# USB0_VBP2APB_WRAP_CONTROLLER_VBP_CORE_ADDR_MAP register map
Vendor: Texas Instruments
Registers are 32-bit, access per field, reset 0x0 unless marked. A register's access mark holds for its fields unless they carry their own. Offsets are as the file gives them; [hi:lo] are bit positions; {n}, {i} and the like mark numbered series.

## USB0_VBP2APB_WRAP_CONTROLLER_VBP_CORE_ADDR_MAP (part 9 of 9)
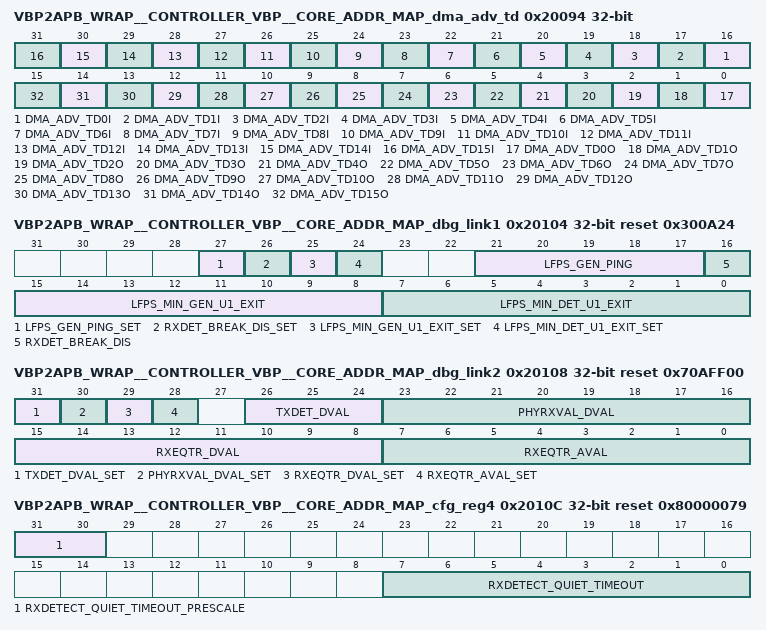
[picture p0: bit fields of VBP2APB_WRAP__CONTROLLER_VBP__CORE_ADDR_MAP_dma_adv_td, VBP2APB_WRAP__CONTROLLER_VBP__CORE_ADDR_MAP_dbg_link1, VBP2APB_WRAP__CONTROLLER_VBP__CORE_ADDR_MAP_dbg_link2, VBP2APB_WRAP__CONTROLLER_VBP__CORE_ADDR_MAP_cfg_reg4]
0x20094 VBP2APB_WRAP__CONTROLLER_VBP__CORE_ADDR_MAP_dma_adv_td rw — DMA Advance TD configuration Register (0 - when stopped during transfer, DMA will advance its address only to the next TRB (+12) start address. 1 - when stopped during transfer (e.g. on USB short packet received in TDL_FROM_TRB mode) DMA will advance its address to the next TD start address). Bits 0..15 applies to EPOUT0..EPOUT15 and bits 16..31 applies to EPIN0..EPIN15
  [n+16] DMA_ADV_TD{n}I (n=0..15) — DMA Advance TD configuration Register for selected Endpoint.
  [n] DMA_ADV_TD{n}O (n=0..15) — DMA Advance TD configuration Register for selected Endpoint.
0x20100 VBP2APB_WRAP__CONTROLLER_VBP__CORE_ADDR_MAP_cfg_reg1 reset 0x38000 — VBUS debouncer Configuration Register 1
  [17:0] DEBOUNCER_CNT rw — This parameter defines the VBUS debouncer delay i.e. the time interval between the VBUS detection on device input and the start of using it internally. Resolution of this parameter is 128 ns. For simulation purposes it is recommended to set the value 1 [128ns] For synthesis purposes it is recommended to set the value 230000 [~30ms]
0x20104 VBP2APB_WRAP__CONTROLLER_VBP__CORE_ADDR_MAP_dbg_link1 reset 0x300A24 — USB3.0 Configuration Register 2
  [27] LFPS_GEN_PING_SET wo — Set the LFPS_GEN_PING_SET value Writing '1' to this bit writes the LFPS_GEN_PING field value to the device. This bit is automatically cleared. Writing '0' has no effect.
  [26] RXDET_BREAK_DIS_SET wo — Set the RXDET_BREAK_DIS value Writing '1' to this bit writes the RXDET_BREAK_DIS field value to the device. This bit is automatically cleared. Writing '0' has no effect.
  [25] LFPS_MIN_GEN_U1_EXIT_SET wo — Set the LFPS_MIN_GEN_U1_EXIT value Writing '1' to this bit writes the LFPS_MIN_GEN_U1_EXIT field value to the device. This bit is automatically cleared. Writing '0' has no effect.
  [24] LFPS_MIN_DET_U1_EXIT_SET wo — Set the LFPS_MIN_DET_U1_EXIT value Writing '1' to this bit writes the LFPS_MIN_DET_U1_EXIT field value to the device. This bit is automatically cleared. Writing '0' has no effect.
  [21:17] LFPS_GEN_PING rw — LFPS_GEN_PING value This parameter configures the LFPS.Ping generation time as shown in the chapter 4. This field is saved to the device only when the field LFPS_GEN_PING_SET is set to '1' during write to the DBG_LINK1 register. Resolution of this parameter is 8 ns. For simulation purposes it is recommended to set the value 24 [~200ns] For synthesis purposes it is recommended to set the value 24 [~200ns]
  [16] RXDET_BREAK_DIS rw — RXDET_BREAK_DIS value This parameter configures terminating the Far-end Receiver termination detection sequence: '0': it is possible that USBSS_DEV will terminate Far-end receiver termination detection sequence '1': USBSS_DEV will not terminate Far-end receiver termination detection sequence The impact of the bit to the link behaviour is shown in chapter 4. This field is saved to the device only when the field RXDET_BREAK_DIS_SET is set to '1' during write to the DBG_LINK1 register.
  [15:8] LFPS_MIN_GEN_U1_EXIT rw — LFPS_MIN_GEN_U1_EXIT value This parameter configures the minimum time for phytxelecidle deassertion when LFPS.U1_Exit signalling is generated as shown in the chapter 4. This field is saved to the device only when the field LFPS_MIN_GEN_U1_EXIT_SET is set to '1' during write to the DBG_LINK1 register. Resolution of this parameter is 8 ns. For simulation purposes it is recommended to set the value 87 [~696ns] For synthesis purposes it is recommended to set the value 87 [~696ns]
  [7:0] LFPS_MIN_DET_U1_EXIT rw — LFPS_MIN_DET_U1_EXIT value This parameter configures the minimum time required for decoding the received LFPS as an LFPS.U1_Exit. Example is shown in the chapter 4. This field is saved to the device only when the field LFPS_MIN_DET_U1_EXIT_SET is set to '1' during write to the DBG_LINK1 register. Resolution of this parameter is 8 ns. For simulation purposes it is recommended to set the value 36 [~300ns]. For synthesis purposes it is recommended to set the value 36 [~300ns].
0x20108 VBP2APB_WRAP__CONTROLLER_VBP__CORE_ADDR_MAP_dbg_link2 reset 0x70AFF00 — USB3.0 Configuration Register 3
  [31] TXDET_DVAL_SET wo — Set the TXDET deassertion value Writing '1' to this bit writes the TXDET_DVAL field value to the device. This bit is automatically cleared. Writing '0' has no effect.
  [30] PHYRXVAL_DVAL_SET wo — Set the Phyrxvalid latency deassertion value Writing '1' to this bit writes the PHYRXVAL_DVAL field value to the device. This bit is automatically cleared. Writing '0' has no effect.0
  [29] RXEQTR_DVAL_SET wo — Set the rxeqtraining deassertion value Writing '1' to this bit writes the RXEQTR_DVAL field value to the device. This bit is automatically cleared. Writing '0' has no effect.
  [28] RXEQTR_AVAL_SET wo — Set the rxeqtraining assertion value Writing '1' to this bit writes the RXEQTR_AVAL field value to the device. This bit is automatically cleared. Writing '0' has no effect.
  [26:24] TXDET_DVAL rw — TXDET deassertion value This parameter configures the phytxdetrx_loop deassertion time after phystatus deassertion during Far-end receiver termination sequence as shown in the chapter 4. This field is saved to the device only when the field TXDET_DVAL_SET is set to '1' during write to the DBG_LINK2 register.
  [23:16] PHYRXVAL_DVAL rw — Phyrxvalid latency deassertion value This parameter enables extending internal phyrxdata and phyrxdatak validity as shown in the chapter 4. This field is saved to the device only when the field PHYRXVAL_DVAL_SET is set to '1' during write to the DBG_LINK2 register.
  [15:8] RXEQTR_DVAL rw — Rxeqtraining deassertion value This parameter configures phyrxeqtraining deasserting time as shown in the chapter 4. This field is saved to the device only when the field RXEQTR_DVAL_SET is set to '1' during write to the DBG_LINK2 register.
  [7:0] RXEQTR_AVAL rw — Rxeqtraining assertion value This parameter configures phyrxeqtraining asserting time as shown in the chapter 4. This field is saved to the device only when the field RXEQTR_AVAL_SET is set to '1' during write to the DBG_LINK2 register.
0x2010C VBP2APB_WRAP__CONTROLLER_VBP__CORE_ADDR_MAP_cfg_reg4 reset 0x80000079 — USB3.0 Configuration Register 4
  [31:30] RXDETECT_QUIET_TIMEOUT_PRESCALE rw — PRESCALER for RXDETECT_QUIET_TIMEOUT : - 0x0 : 8ns [PHY pclk clock] - 0x1 : 1us - 0x2 : 100us - 0x3 : no clock - allows disabling certain timeout
  [7:0] RXDETECT_QUIET_TIMEOUT rw — RXDETECT_QUIET_TIMEOUT value Resolution of this parameter is selected by RXDETECT_QUIET_TIMEOUT_PRESCALE. For simulation purposes it is recommended to set the value: - 11*100us =~1ms [SystemC device ENV] - 13*1us =~12us [VIP based ENV] For synthesis purposes it is recommended to set the value 121*100us =~12ms
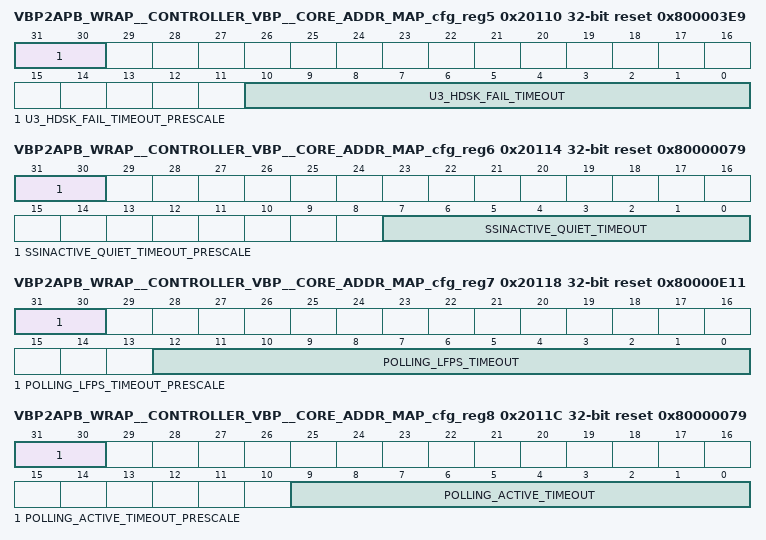
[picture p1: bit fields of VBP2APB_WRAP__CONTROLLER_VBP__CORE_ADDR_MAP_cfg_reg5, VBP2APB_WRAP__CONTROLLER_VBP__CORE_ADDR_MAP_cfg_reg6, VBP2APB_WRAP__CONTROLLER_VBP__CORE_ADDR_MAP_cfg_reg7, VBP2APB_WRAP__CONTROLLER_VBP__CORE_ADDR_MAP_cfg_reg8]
0x20110 VBP2APB_WRAP__CONTROLLER_VBP__CORE_ADDR_MAP_cfg_reg5 reset 0x800003E9 — USB3.0 Configuration Register 5
  [31:30] U3_HDSK_FAIL_TIMEOUT_PRESCALE rw — PRESCALER for U3_HDSK_FAIL_TIMEOUT : - 0x0 : 8ns [PHY pclk clock] - 0x1 : 1us - 0x2 : 100us - 0x3 : no clock - allows disabling certain timeout
  [10:0] U3_HDSK_FAIL_TIMEOUT rw — U3_HDSK_FAIL_TIMEOUT value Resolution of this parameter is selected by U3_HDSK_FAIL_TIMEOUT_PRESCALE. For simulation purposes it is recommended to set the value: - 11*100us =~1ms [SystemC device ENV] - 11*100us =~1ms [VIP based ENV] For synthesis purposes it is recommended to set the value 1001*100us =~100ms
0x20114 VBP2APB_WRAP__CONTROLLER_VBP__CORE_ADDR_MAP_cfg_reg6 reset 0x80000079 — Configuration Register 6
  [31:30] SSINACTIVE_QUIET_TIMEOUT_PRESCALE rw — PRESCALER for SSINACTIVE_QUIET_TIMEOUT value: - 0x0 : 8ns [PHY pclk clock] - 0x1 : 1us - 0x2 : 100us - 0x3 : no clock - allows disabling certain timeout
  [7:0] SSINACTIVE_QUIET_TIMEOUT rw — SSINACTIVE_QUIET_TIMEOUT value Resolution of this parameter is selected by SSINACTIVE_QUIET_TIMEOUT_PRESCALE. For simulation purposes it is recommended to set the value: - 11*100us =~1ms [SystemC device ENV] - 13*1us =~12us [VIP based ENV] For synthesis purposes it is recommended to set the value: - 121*100us =~12ms
0x20118 VBP2APB_WRAP__CONTROLLER_VBP__CORE_ADDR_MAP_cfg_reg7 reset 0x80000E11 — USB3.0 Configuration Register 7
  [31:30] POLLING_LFPS_TIMEOUT_PRESCALE rw — PRESCALER for POLLING_LFPS_TIMEOUT value: - 0x0 : 8ns [PHY pclk clock] - 0x1 : 1us - 0x2 : 100us - 0x3 : no clock - allows disabling certain timeout
  [12:0] POLLING_LFPS_TIMEOUT rw — POLLING_LFPS_TIMEOUT value Resolution of this parameter is selected by POLLING_LFPS_TIMEOUT_PRESCALE. For simulation purposes it is recommended to set the value: - 11*100us =~1ms [SystemC device ENV] - 481*1us =~480us [VIP based ENV] For synthesis purposes it is recommended to set the value: - 3601*100us =~360ms
0x2011C VBP2APB_WRAP__CONTROLLER_VBP__CORE_ADDR_MAP_cfg_reg8 reset 0x80000079 — USB3.0 Configuration Register 8
  [31:30] POLLING_ACTIVE_TIMEOUT_PRESCALE rw — PRESCALER for POLLING_ACTIVE_TIMEOUT value: - 0x0 : 8ns [PHY pclk clock] - 0x1 : 1us - 0x2 : 100us - 0x3 : no clock - allows disabling certain timeout
  [9:0] POLLING_ACTIVE_TIMEOUT rw — POLLING_ACTIVE_TIMEOUT value Resolution of this parameter is selected by POLLING_ACTIVE_TIMEOUT_PRESCALE. For simulation purposes it is recommended to set the value: - 11*100us =~1ms [SystemC device ENV] - 31*1us =~30us [VIP based ENV] For synthesis purposes it is recommended to set the value: - 121*100us =~12ms
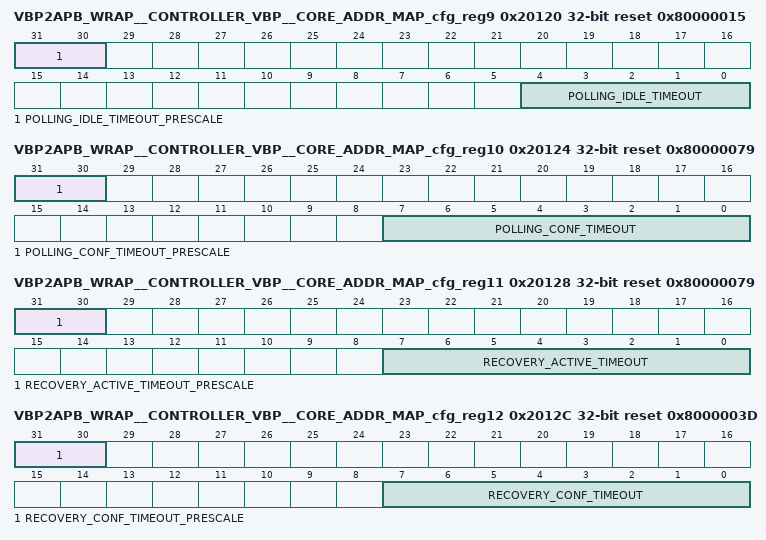
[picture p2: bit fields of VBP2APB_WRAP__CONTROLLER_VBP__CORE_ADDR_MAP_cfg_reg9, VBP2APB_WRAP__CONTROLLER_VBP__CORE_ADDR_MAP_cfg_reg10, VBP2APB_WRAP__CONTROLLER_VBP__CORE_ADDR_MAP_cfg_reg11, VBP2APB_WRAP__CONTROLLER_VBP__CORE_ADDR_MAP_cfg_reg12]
0x20120 VBP2APB_WRAP__CONTROLLER_VBP__CORE_ADDR_MAP_cfg_reg9 reset 0x80000015 — USB3.0 Configuration Register 9
  [31:30] POLLING_IDLE_TIMEOUT_PRESCALE rw — PRESCALER for POLLING_IDLE_TIMEOUT value: - 0x0 : 8ns [PHY pclk clock] - 0x1 : 1us - 0x2 : 100us - 0x3 : no clock - allows disabling certain timeout
  [4:0] POLLING_IDLE_TIMEOUT rw — POLLING_IDLE_TIMEOUT value Resolution of this parameter is selected by POLLING_IDLE_TIMEOUT_PRESCALE. For simulation purposes it is recommended to set the value: - 21*100us =~2ms [SystemC device ENV] - 3*1us =~2us [VIP based ENV] For synthesis purposes it is recommended to set the value: - 21*100us =~2ms
0x20124 VBP2APB_WRAP__CONTROLLER_VBP__CORE_ADDR_MAP_cfg_reg10 reset 0x80000079 — USB3.0 Configuration Register 10
  [31:30] POLLING_CONF_TIMEOUT_PRESCALE rw — PRESCALER for POLLING_CONF_TIMEOUT value: - 0x0 : 8ns [PHY pclk clock] - 0x1 : 1us - 0x2 : 100us - 0x3 : no clock - allows disabling certain timeout
  [7:0] POLLING_CONF_TIMEOUT rw — POLLING_CONF_TIMEOUT value Resolution of this parameter is selected by POLLING_CONF_TIMEOUT_PRESCALE. For simulation purposes it is recommended to set the value: - 11*100us =~1ms [SystemC device ENV] - 31*1us =~30us [VIP based ENV] For synthesis purposes it is recommended to set the value: - 121*100us =~12ms
0x20128 VBP2APB_WRAP__CONTROLLER_VBP__CORE_ADDR_MAP_cfg_reg11 reset 0x80000079 — USB3.0 Configuration Register 11
  [31:30] RECOVERY_ACTIVE_TIMEOUT_PRESCALE rw — PRESCALER for RECOVERY_ACTIVE_TIMEOUT value: - 0x0 : 8ns [PHY pclk clock] - 0x1 : 1us - 0x2 : 100us - 0x3 : no clock - allows disabling certain timeout
  [7:0] RECOVERY_ACTIVE_TIMEOUT rw — RECOVERY_ACTIVE_TIMEOUT value Resolution of this parameter is selected by RECOVERY_ACTIVE_TIMEOUT_PRESCALE. For simulation purposes it is recommended to set the value: - 11*100us =~1ms [SystemC device ENV] - 101*1us =~100us [VIP based ENV] For synthesis purposes it is recommended to set the value: - 121*100us =~12ms
0x2012C VBP2APB_WRAP__CONTROLLER_VBP__CORE_ADDR_MAP_cfg_reg12 reset 0x8000003D — USB3.0 Configuration Register 12
  [31:30] RECOVERY_CONF_TIMEOUT_PRESCALE rw — PRESCALER for RECOVERY_CONF_TIMEOUT value: - 0x0 : 8ns [PHY pclk clock] - 0x1 : 1us - 0x2 : 100us - 0x3 : no clock - allows disabling certain timeout
  [7:0] RECOVERY_CONF_TIMEOUT rw — RECOVERY_CONF_TIMEOUT value Resolution of this parameter is selected by RECOVERY_CONF_TIMEOUT_PRESCALE. For simulation purposes it is recommended to set the value: - 11*100us =~1ms [SystemC device ENV] - 101*1us =~100us [VIP based ENV] For synthesis purposes it is recommended to set the value: - 61*100us =~6ms
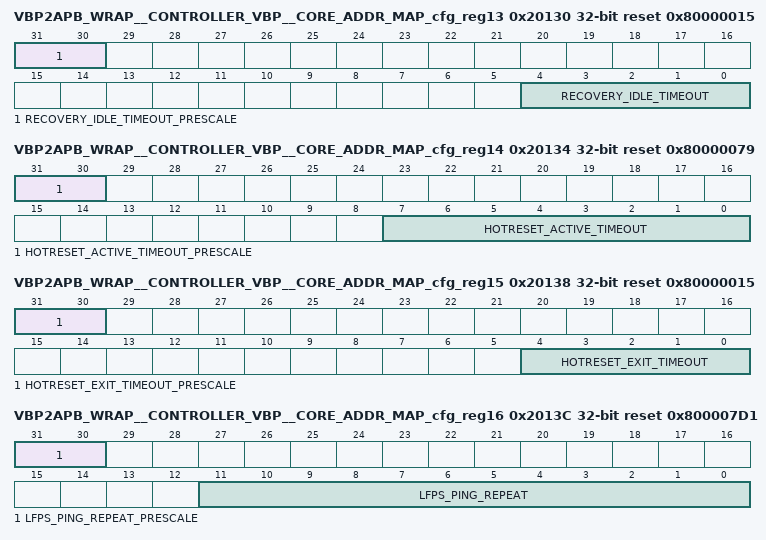
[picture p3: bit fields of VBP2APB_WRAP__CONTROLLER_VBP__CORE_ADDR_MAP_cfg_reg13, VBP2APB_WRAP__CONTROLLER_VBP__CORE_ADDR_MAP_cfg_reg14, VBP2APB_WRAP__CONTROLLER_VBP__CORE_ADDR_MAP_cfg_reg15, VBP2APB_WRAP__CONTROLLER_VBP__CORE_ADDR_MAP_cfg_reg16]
0x20130 VBP2APB_WRAP__CONTROLLER_VBP__CORE_ADDR_MAP_cfg_reg13 reset 0x80000015 — USB3.0 Configuration Register 13
  [31:30] RECOVERY_IDLE_TIMEOUT_PRESCALE rw — PRESCALER for RECOVERY_IDLE_TIMEOUT value: - 0x0 : 8ns [PHY pclk clock] - 0x1 : 1us - 0x2 : 100us - 0x3 : no clock - allows disabling certain timeout
  [4:0] RECOVERY_IDLE_TIMEOUT rw — RECOVERY_IDLE_TIMEOUT value Resolution of this parameter is selected by RECOVERY_IDLE_TIMEOUT_PRESCALE. For simulation purposes it is recommended to set the value: - 21*100us =~2ms [SystemC device ENV] - 3*1us =~3us [VIP based ENV] For synthesis purposes it is recommended to set the value: - 21*100us =~2ms
0x20134 VBP2APB_WRAP__CONTROLLER_VBP__CORE_ADDR_MAP_cfg_reg14 reset 0x80000079 — USB3.0 Configuration Register 14
  [31:30] HOTRESET_ACTIVE_TIMEOUT_PRESCALE rw — PRESCALER for HOTRESET_ACTIVE_TIMEOUT value: - 0x0 : 8ns [PHY pclk clock] - 0x1 : 1us - 0x2 : 100us - 0x3 : no clock - allows disabling certain timeout
  [7:0] HOTRESET_ACTIVE_TIMEOUT rw — HOTRESET_ACTIVE_TIMEOUT value Resolution of this parameter is selected by HOTRESET_ACTIVE_TIMEOUT_PRESCALE. For simulation purposes it is recommended to set the value: - 21*100us =~2ms [SystemC device ENV] - 13*1us =~13us [VIP based ENV] For synthesis purposes it is recommended to set the value: - 121*100us =~12ms
0x20138 VBP2APB_WRAP__CONTROLLER_VBP__CORE_ADDR_MAP_cfg_reg15 reset 0x80000015 — USB3.0 Configuration Register 15
  [31:30] HOTRESET_EXIT_TIMEOUT_PRESCALE rw — PRESCALER for HOTRESET_EXIT_TIMEOUT value: - 0x0 : 8ns [PHY pclk clock] - 0x1 : 1us - 0x2 : 100us - 0x3 : no clock - allows disabling certain timeout
  [4:0] HOTRESET_EXIT_TIMEOUT rw — HOTRESET_EXIT_TIMEOUT value Resolution of this parameter is selected by HOTRESET_EXIT_TIMEOUT_PRESCALE. For simulation purposes it is recommended to set the value: - 21*100us =~2ms [SystemC device ENV] - 3*1us =~3us [VIP based ENV] For synthesis purposes it is recommended to set the value: - 21*100us =~2ms
0x2013C VBP2APB_WRAP__CONTROLLER_VBP__CORE_ADDR_MAP_cfg_reg16 reset 0x800007D1 — USB3.0 Configuration Register 16
  [31:30] LFPS_PING_REPEAT_PRESCALE rw — PRESCALER for LFPS_PING_REPEAT value: - 0x0 : 8ns [PHY pclk clock] - 0x1 : 1us - 0x2 : 100us - 0x3 : no clock - allows disabling certain timeout
  [11:0] LFPS_PING_REPEAT rw — LFPS_PING_REPEAT value Resolution of this parameter is selected by LFPS_PING_REPEAT_PRESCALE. For simulation purposes it is recommended to set the value: - 6*100us =~0.5ms [SystemC device ENV] - 4*100us =~400us [VIP based ENV] For synthesis purposes it is recommended to set the value: - 2001*100us =~200ms
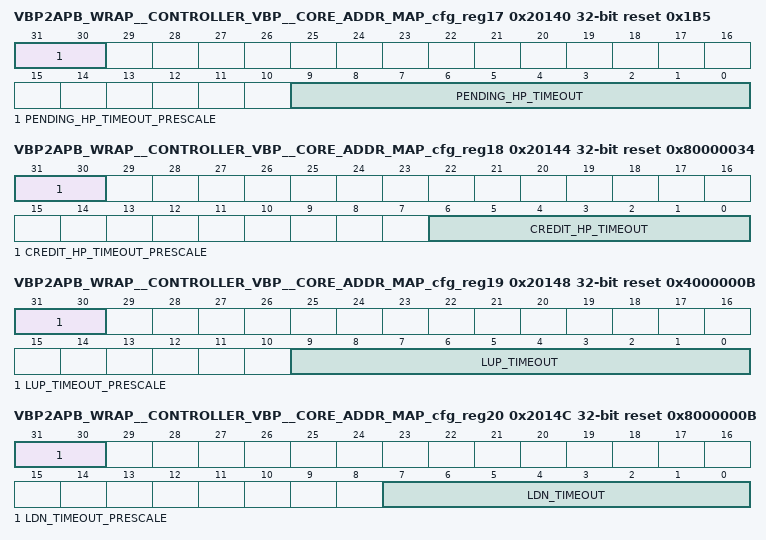
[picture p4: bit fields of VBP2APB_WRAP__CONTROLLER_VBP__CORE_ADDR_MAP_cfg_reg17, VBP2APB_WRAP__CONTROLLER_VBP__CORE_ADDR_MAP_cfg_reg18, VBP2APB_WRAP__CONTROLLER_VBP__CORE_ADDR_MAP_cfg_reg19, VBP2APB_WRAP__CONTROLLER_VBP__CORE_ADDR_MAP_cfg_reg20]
0x20140 VBP2APB_WRAP__CONTROLLER_VBP__CORE_ADDR_MAP_cfg_reg17 reset 0x1B5 — USB3.0 Configuration Register 17
  [31:30] PENDING_HP_TIMEOUT_PRESCALE rw — PRESCALER for PENDING_HP_TIMEOUT value: - 0x0 : 8ns [PHY pclk clock] - 0x1 : 1us - 0x2 : 100us - 0x3 : no clock - allows disabling certain timeout
  [9:0] PENDING_HP_TIMEOUT rw — PENDING_HP_TIMEOUT value Resolution of this parameter is selected by PENDING_HP_TIMEOUT_PRESCALE. For simulation purposes it is recommended to set the value: - 437*8ns =~3.5us [SystemC device ENV] - 437*8ns =~3.5us [VIP based ENV] For synthesis purposes it is recommended to set the value: - 437*8ns =~3.5us
0x20144 VBP2APB_WRAP__CONTROLLER_VBP__CORE_ADDR_MAP_cfg_reg18 reset 0x80000034 — USB3.0 Configuration Register 18
  [31:30] CREDIT_HP_TIMEOUT_PRESCALE rw — PRESCALER for CREDIT_HP_TIMEOUT value: - 0x0 : 8ns [PHY pclk clock] - 0x1 : 1us - 0x2 : 100us - 0x3 : no clock - allows disabling certain timeout
  [6:0] CREDIT_HP_TIMEOUT rw — CREDIT_HP_TIMEOUT value Resolution of this parameter is selected by CREDIT_HP_TIMEOUT_PRESCALE. For simulation purposes it is recommended to set the value: - 11*100us =~1ms [SystemC device ENV] - 11*100us =~1ms [VIP based ENV] For synthesis purposes it is recommended to set the value: - 52*100us =~5.1ms
0x20148 VBP2APB_WRAP__CONTROLLER_VBP__CORE_ADDR_MAP_cfg_reg19 reset 0x4000000B — USB3.0 Configuration Register 19
  [31:30] LUP_TIMEOUT_PRESCALE rw — PRESCALER for LUP_TIMEOUT value: - 0x0 : 8ns [PHY pclk clock] - 0x1 : 1us - 0x2 : 100us - 0x3 : no clock - allows disabling certain timeout
  [9:0] LUP_TIMEOUT rw — LUP_TIMEOUT value Resolution of this parameter is selected by LUP_TIMEOUT_PRESCALE. For simulation purposes it is recommended to set the value: - 11*1us =~11us [SystemC device ENV] - 11*1us =~11us [VIP based ENV] For synthesis purposes it is recommended to set the value: - 11*1us =~11us
0x2014C VBP2APB_WRAP__CONTROLLER_VBP__CORE_ADDR_MAP_cfg_reg20 reset 0x8000000B — USB3.0 Configuration Register 20
  [31:30] LDN_TIMEOUT_PRESCALE rw — PRESCALER for LDN_TIMEOUT value: - 0x0 : 8ns [PHY pclk clock] - 0x1 : 1us - 0x2 : 100us - 0x3 : no clock - allows disabling certain timeout
  [7:0] LDN_TIMEOUT rw — LDN_TIMEOUT value Resolution of this parameter is selected by LDN_TIMEOUT_PRESCALE. For simulation purposes it is recommended to set the value: - 11*100us =~1ms [SystemC device ENV] - 129*1us =~129us [VIP based ENV] For synthesis purposes it is recommended to set the value: - 11*100us =~1ms
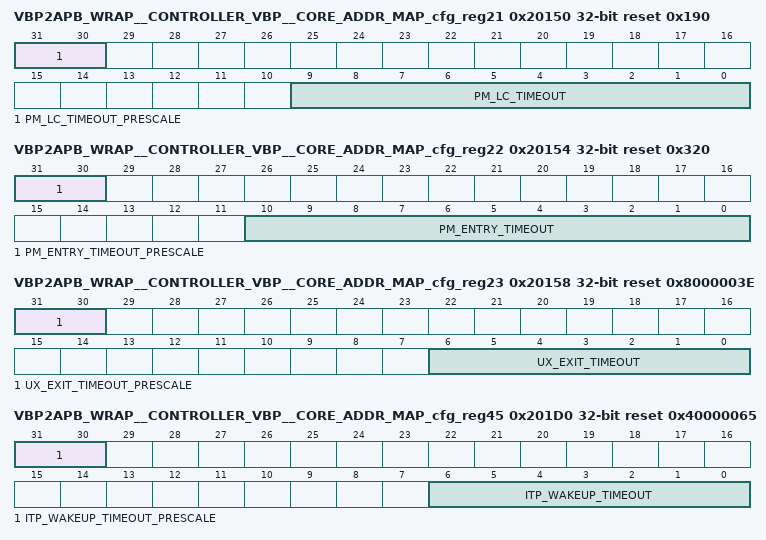
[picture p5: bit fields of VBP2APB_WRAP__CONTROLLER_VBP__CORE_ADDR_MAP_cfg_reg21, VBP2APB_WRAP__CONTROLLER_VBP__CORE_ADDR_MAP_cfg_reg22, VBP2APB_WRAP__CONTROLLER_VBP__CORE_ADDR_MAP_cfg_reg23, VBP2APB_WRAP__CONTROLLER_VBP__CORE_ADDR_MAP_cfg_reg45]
0x20150 VBP2APB_WRAP__CONTROLLER_VBP__CORE_ADDR_MAP_cfg_reg21 reset 0x190 — USB3.0 Configuration Register 21
  [31:30] PM_LC_TIMEOUT_PRESCALE rw — PRESCALER for PM_LC_TIMEOUT value: - 0x0 : 8ns [PHY pclk clock] - 0x1 : 1us - 0x2 : 100us - 0x3 : no clock - allows disabling certain timeout
  [9:0] PM_LC_TIMEOUT rw — PM_LC_TIMEOUT value Resolution of this parameter is selected by PM_LC_TIMEOUT_PRESCALE. For simulation purposes it is recommended to set the value: - 400*8ns =~3.2us [SystemC device ENV] - 400*8ns =~3.2us [VIP based ENV] For synthesis purposes it is recommended to set the value: - 400*8ns =~3.2us
0x20154 VBP2APB_WRAP__CONTROLLER_VBP__CORE_ADDR_MAP_cfg_reg22 reset 0x320 — USB3.0 Configuration Register 22
  [31:30] PM_ENTRY_TIMEOUT_PRESCALE rw — PRESCALER for PM_ENTRY_TIMEOUT value: - 0x0 : 8ns [PHY pclk clock] - 0x1 : 1us - 0x2 : 100us - 0x3 : no clock - allows disabling certain timeout
  [10:0] PM_ENTRY_TIMEOUT rw — PM_ENTRY_TIMEOUT value Resolution of this parameter is selected by PM_ENTRY_TIMEOUT_PRESCALE. For simulation purposes it is recommended to set the value: - 800*8ns =~6.4us [SystemC device ENV] - 800*8ns =~6.4us [VIP based ENV] For synthesis purposes it is recommended to set the value: - 800*8ns =~6.4us
0x20158 VBP2APB_WRAP__CONTROLLER_VBP__CORE_ADDR_MAP_cfg_reg23 reset 0x8000003E — USB3.0 Configuration Register 23
  [31:30] UX_EXIT_TIMEOUT_PRESCALE rw — PRESCALER for UX_EXIT_TIMEOUT value: - 0x0 : 8ns [PHY pclk clock] - 0x1 : 1us - 0x2 : 100us - 0x3 : no clock - allows disabling certain timeout
  [6:0] UX_EXIT_TIMEOUT rw — UX_EXIT_TIMEOUT value Resolution of this parameter is selected by UX_EXIT_TIMEOUT_PRESCALE. For simulation purposes it is recommended to set the value: - 8*100us =~800us [SystemC device ENV] - 3*100us =~300us [VIP based ENV] For synthesis purposes it is recommended to set the value: - 62*100us =~6.2ms
0x2015C VBP2APB_WRAP__CONTROLLER_VBP__CORE_ADDR_MAP_cfg_reg24 reset 0x243D58 — USB3.0 Configuration Register 24
  [22:0] LFPS_DET_RESET_MIN rw — LFPS_DET_RESET_MIN value Resolution of this parameter is 8 ns. For simulation purposes it is recommended to set the value 395833 [~3.16ms] For synthesis purposes it is recommended to set the value 2375000 [~19ms]
0x20160 VBP2APB_WRAP__CONTROLLER_VBP__CORE_ADDR_MAP_cfg_reg25 reset 0xE4E1C0 — USB3.0 Configuration Register 25
  [23:0] LFPS_DET_RESET_MAX rw — LFPS_DET_RESET_MAX value Resolution of this parameter is 8 ns. For simulation purposes it is recommended to set the value 5000000 [~40ms] For synthesis purposes it is recommended to set the value 15000000 [~120ms]
0x20164 VBP2APB_WRAP__CONTROLLER_VBP__CORE_ADDR_MAP_cfg_reg26 reset 0x4B — USB3.0 Configuration Register 26
  [6:0] LFPS_DET_POLLING_MIN rw — LFPS_DET_POLLING_MIN value Resolution of this parameter is 8 ns. For simulation purposes it is recommended to set the value 75 [~0.6us] For synthesis purposes it is recommended to set the value 75 [~0.6us]
0x20168 VBP2APB_WRAP__CONTROLLER_VBP__CORE_ADDR_MAP_cfg_reg27 reset 0xBB — USB3.0 Configuration Register 27
  [7:0] LFPS_DET_POLLING_MAX rw — LFPS_DET_POLLING_MAX value Resolution of this parameter is 8 ns. For simulation purposes it is recommended to set the value 175 [~1.4us] For synthesis purposes it is recommended to set the value 175 [~1.4us]
0x2016C VBP2APB_WRAP__CONTROLLER_VBP__CORE_ADDR_MAP_cfg_reg28 reset 0x4 — USB3.0 Configuration Register 28
  [2:0] LFPS_DET_PING_MIN rw — LFPS_DET_PING_MIN value Resolution of this parameter is 8 ns. For simulation purposes it is recommended to set the value 4 [~40ns] For synthesis purposes it is recommended to set the value 4 [~40ns]
0x20170 VBP2APB_WRAP__CONTROLLER_VBP__CORE_ADDR_MAP_cfg_reg29 reset 0x17 — USB3.0 Configuration Register 29
  [4:0] LFPS_DET_PING_MAX rw — LFPS_DET_PING_MAX value Resolution of this parameter is 8 ns. For simulation purposes it is recommended to set the value 23 [~200ns] For synthesis purposes it is recommended to set the value 23 [~200ns]
0x20174 VBP2APB_WRAP__CONTROLLER_VBP__CORE_ADDR_MAP_cfg_reg30 reset 0x24 — USB3.0 Configuration Register 30 Note: In current version of the core this register is not implemented. Functionality of this register is provided by DBG_LINK1.LFPS_MIN_DET_U1_EXIT register.
  [5:0] LFPS_DET_U1EXIT_MIN rw — LFPS_DET_U1EXIT_MIN value Resolution of this parameter is 8 ns. For simulation purposes it is recommended to set the value 36 [~300ns] For synthesis purposes it is recommended to set the value 36 [~300ns]
0x20178 VBP2APB_WRAP__CONTROLLER_VBP__CORE_ADDR_MAP_cfg_reg31 reset 0x6F — USB3.0 Configuration Register 31
  [6:0] LFPS_DET_U1EXIT_MAX rw — LFPS_DET_U1EXIT_MAX value Resolution of this parameter is 8 ns. For simulation purposes it is recommended to set the value 111 [~900ns] For synthesis purposes it is recommended to set the value 111 [~900ns]
0x2017C VBP2APB_WRAP__CONTROLLER_VBP__CORE_ADDR_MAP_cfg_reg32 reset 0x24 — USB3.0 Configuration Register 32
  [5:0] LFPS_DET_U2EXIT_MIN rw — LFPS_DET_U2EXIT_MIN value Resolution of this parameter is 8 ns. For simulation purposes it is recommended to set the value 36 [~300ns] For synthesis purposes it is recommended to set the value 36 [~300ns]
0x20180 VBP2APB_WRAP__CONTROLLER_VBP__CORE_ADDR_MAP_cfg_reg33 reset 0x3D090 — USB3.0 Configuration Register 33
  [17:0] LFPS_DET_U2EXIT_MAX rw — LFPS_DET_U2EXIT_MAX value Resolution of this parameter is 8 ns. For simulation purposes it is recommended to set the value 250000 [~2ms] For synthesis purposes it is recommended to set the value 250000 [~2ms]
0x20184 VBP2APB_WRAP__CONTROLLER_VBP__CORE_ADDR_MAP_cfg_reg34 reset 0x24 — USB3.0 Configuration Register 34
  [5:0] LFPS_DET_U3EXIT_MIN rw — LFPS_DET_U3EXIT_MIN value Resolution of this parameter is 8 ns. For simulation purposes it is recommended to set the value 36 [~300ns] For synthesis purposes it is recommended to set the value 36 [~300ns]
0x20188 VBP2APB_WRAP__CONTROLLER_VBP__CORE_ADDR_MAP_cfg_reg35 reset 0x1312D0 — USB3.0 Configuration Register 35
  [20:0] LFPS_DET_U3EXIT_MAX rw — LFPS_DET_U3EXIT_MAX value Resolution of this parameter is 8 ns. For simulation purposes it is recommended to set the value 1250000 [~10ms] For synthesis purposes it is recommended to set the value 1250000 [~10ms]
0x201AC VBP2APB_WRAP__CONTROLLER_VBP__CORE_ADDR_MAP_cfg_reg36 reset 0x18 — USB3.0 Configuration Register 36 Note: In current version of the core this register is not implemented. Functionality of this register is provided by DBG_LINK1.LFPS_GEN_PING register.
  [4:0] LFPS_GEN_PING rw — LFPS_GEN_PING value Resolution of this parameter is 8 ns. For simulation purposes it is recommended to set the value 24 [~200ns] For synthesis purposes it is recommended to set the value 24 [~200ns]
0x201B0 VBP2APB_WRAP__CONTROLLER_VBP__CORE_ADDR_MAP_cfg_reg37 reset 0x7D — USB3.0 Configuration Register 37
  [7:0] LFPS_GEN_POLLING rw — LFPS_GEN_POLLING value Resolution of this parameter is 8 ns. For simulation purposes it is recommended to set the value 125 [~1us] For synthesis purposes it is recommended to set the value 125 [~1us]
0x201B4 VBP2APB_WRAP__CONTROLLER_VBP__CORE_ADDR_MAP_cfg_reg38 reset 0x3D090 — USB3.0 Configuration Register 38
  [17:0] LFPS_GEN_U1EXIT rw — LFPS_GEN_U1EXIT value Resolution of this parameter is 8 ns. For simulation purposes it is recommended to set the value 62500 [~500us] For synthesis purposes it is recommended to set the value 250000 [~2ms]
0x201B8 VBP2APB_WRAP__CONTROLLER_VBP__CORE_ADDR_MAP_cfg_reg39 reset 0x1312D0 — USB3.0 Configuration Register 39
  [20:0] LFPS_GEN_U3EXIT rw — LFPS_GEN_U3EXIT value Resolution of this parameter is 8 ns. For simulation purposes it is recommended to set the value 125000 [~1ms] For synthesis purposes it is recommended to set the value 1250000 [~10ms]
0x201BC VBP2APB_WRAP__CONTROLLER_VBP__CORE_ADDR_MAP_cfg_reg40 reset 0x1F — USB3.0 Configuration Register 40 Note: In current version of the core this register is not implemented. Functionality of this register is provided by DBG_LINK1.LFPS_MIN_GEN_U1_EXIT register.
  [6:0] LFPS_MIN_GEN_U1EXIT rw — LFPS_MIN_GEN_U1EXIT value Resolution of this parameter is 8 ns. For simulation purposes it is recommended to set the value 87 [~696ns] For synthesis purposes it is recommended to set the value 87 [~696ns]
0x201C0 VBP2APB_WRAP__CONTROLLER_VBP__CORE_ADDR_MAP_cfg_reg41 reset 0x30D4 — USB3.0 Configuration Register 41
  [14:0] LFPS_MIN_GEN_U2EXIT rw — LFPS_MIN_GEN_U2EXIT value Resolution of this parameter is 8 ns. For simulation purposes it is recommended to set the value 12500 [~100us] For synthesis purposes it is recommended to set the value 12500 [~100us]
0x201C4 VBP2APB_WRAP__CONTROLLER_VBP__CORE_ADDR_MAP_cfg_reg42 reset 0x4E2 — USB3.0 Configuration Register 42
  [10:0] LFPS_POLLING_REPEAT rw — LFPS_POLLING_REPEAT value Resolution of this parameter is 8 ns. For simulation purposes it is recommended to set the value 1250 [~10us] For synthesis purposes it is recommended to set the value 1250 [~10us]
0x201C8 VBP2APB_WRAP__CONTROLLER_VBP__CORE_ADDR_MAP_cfg_reg43 reset 0x6D6 — USB3.0 Configuration Register 43
  [10:0] LFPS_POLLING_MAX_TREPEAT rw — LFPS_POLLING_MAX_TREPEAT value Resolution of this parameter is 8 ns. For simulation purposes it is recommended to set the value 1750 [~14us] For synthesis purposes it is recommended to set the value 1750 [~14us]
0x201CC VBP2APB_WRAP__CONTROLLER_VBP__CORE_ADDR_MAP_cfg_reg44 reset 0x2EC — USB3.0 Configuration Register 44
  [10:0] LFPS_POLLING_MIN_TREPEAT rw — LFPS_POLLING_MIN_TREPEAT value Resolution of this parameter is 8 ns. For simulation purposes it is recommended to set the value 748 [~6us] For synthesis purposes it is recommended to set the value 748 [~6us]
0x201D0 VBP2APB_WRAP__CONTROLLER_VBP__CORE_ADDR_MAP_cfg_reg45 reset 0x40000065 — USB3.0 Configuration Register 45
  [31:30] ITP_WAKEUP_TIMEOUT_PRESCALE rw — PRESCALER for ITP_WAKEUP_TIMEOUT value: - 0x0 : 8ns [PHY pclk clock] - 0x1 : 1us - 0x2 : 100us - 0x3 : no clock - allows disabling certain timeout
  [6:0] ITP_WAKEUP_TIMEOUT rw — ITP_WAKEUP_TIMEOUT value Resolution of this parameter is selected by ITP_WAKEUP_TIMEOUT_PRESCALE. For simulation purposes it is recommended to set the value: - 101*1us =~100us [SystemC device ENV] - 101*1us =~100us [VIP based ENV] For synthesis purposes it is recommended to set the value: - 101*1us =~100us
0x201D4 VBP2APB_WRAP__CONTROLLER_VBP__CORE_ADDR_MAP_cfg_reg46 reset 0xFFFF — USB3.0 Configuration Register 46
  [15:0] TSEQ_QUANTITY rw — TSEQ_QUANTITY value This parameter defines the number of TSEQ training sequences to be sent during Polling.RxEq state. For simulation purposes it is recommended to set the value 655 For synthesis purposes it is recommended to set the value 65535.
0x201D8 VBP2APB_WRAP__CONTROLLER_VBP__CORE_ADDR_MAP_cfg_reg47 reset 0x7D001 — USB3.0 Configuration Register 47
  [19:0] ERDY_TIMEOUT_CNT rw — ERDY_TIMEOUT_CNT value Resolution of this parameter is 1 us. For simulation purposes it is recommended to set the value 16 [~15 us] For synthesis purposes it is recommended to set the value ~512001 [~512ms]
0x201DC VBP2APB_WRAP__CONTROLLER_VBP__CORE_ADDR_MAP_cfg_reg48 reset 0x18000 — USB2.0 Configuration Register 48
  [17:0] TWTRSTFS_J_CNT rw — Time a device operating in full speed must wait before begin the transition to the Suspend state after it see a constant Idle state on their upstream facing bus lines. Resolution of this parameter is 33.3 ns. For simulation purposes it is recommended to set the value 98304 [~3.28ms] For synthesis purposes it is recommended to set the value 98304 [~3.28ms]
0x201E0 VBP2APB_WRAP__CONTROLLER_VBP__CORE_ADDR_MAP_cfg_reg49 reset 0x8B00 — USB2.0 Configuration Register 49
  [15:0] TUCH_CNT rw — TUCH: Minimum duration of a Chirp K from a high-speed capable device within the reset protocol. Resolution of this parameter is 33.3 ns. For simulation purposes it is recommended to set the value 129 [~4.3us] For synthesis purposes it is recommended to set the value 35584 [~1.19ms]
0x201E4 VBP2APB_WRAP__CONTROLLER_VBP__CORE_ADDR_MAP_cfg_reg50 reset 0x960 — USB2.0 Configuration Register 50
  [11:0] TWAITCHK_CNT rw — Time to wait before device will start to drive Chirp K after detecting reset signalling. Resolution of this parameter is 33.3 ns. For simulation purposes it is recommended to set the value 30 [~1us] For synthesis purposes it is recommended to set the value 2400 [~80us]
0x201E8 VBP2APB_WRAP__CONTROLLER_VBP__CORE_ADDR_MAP_cfg_reg51 reset 0x19A03 — USB2.0 Configuration Register 51
  [16:0] TWTFS_CNT rw — TWTFS: Time after end of upstream chirp at which device reverts to full speed default state if no downstream chirp is detected. Resolution of this parameter is 33.3 ns. For simulation purposes it is recommended to set the value 1000 [~33.3us] For synthesis purposes it is recommended to set the value 104963 [~3.5ms]
0x201EC VBP2APB_WRAP__CONTROLLER_VBP__CORE_ADDR_MAP_cfg_reg52 reset 0x16000 — USB2.0 Configuration Register 52
  [16:0] TWTREV_CNT rw — TWTREV: Time a high-speed capable device operating in high-speed must wait after start of SE0 before reverting to full-speed. Resolution of this parameter is 33.3 ns. For simulation purposes it is recommended to set the value 90112 [~3ms] For synthesis purposes it is recommended to set the value 90112 [~3ms]
0x201F0 VBP2APB_WRAP__CONTROLLER_VBP__CORE_ADDR_MAP_cfg_reg53 reset 0x5C00 — USB2.0 Configuration Register 53
  [14:0] TWTRSTHS_CNT rw — TWTRSTHS: Time a device must wait after reverting to full-speed before sampling the bus state for SE0 and beginning the high-speed detection handshake. Resolution of this parameter is 33.3 ns. For simulation purposes it is recommended to set the value 23552 [~785us] For synthesis purposes it is recommended to set the value 23552 [~785us]
0x201F4 VBP2APB_WRAP__CONTROLLER_VBP__CORE_ADDR_MAP_cfg_reg54 reset 0x24A00 — USB2.0 Configuration Register 54
  [17:0] TWTRSM_CNT rw — TWTRSM: Period of idle bus before device can initiate resume. Resolution of this parameter is 33.3 ns. For simulation purposes it is recommended to set the value 150016 [~5ms] For synthesis purposes it is recommended to set the value 150016 [~5ms]
0x201F8 VBP2APB_WRAP__CONTROLLER_VBP__CORE_ADDR_MAP_cfg_reg55 reset 0x8000 — USB2.0 Configuration Register 55
  [15:0] TDRSMUP_CNT rw — TDRSMUP: Duration of driving resume upstream. Resolution of this parameter is 33.3 ns. For simulation purposes it is recommended to set the value 32768 [~1.1ms] For synthesis purposes it is recommended to set the value 32768 [~1.1ms]
0x201FC VBP2APB_WRAP__CONTROLLER_VBP__CORE_ADDR_MAP_cfg_reg56 reset 0x30 — USB2.0 Configuration Register 56
  [5:0] TOUTHS_CNT rw — Time after device expecting a response to a transmission will timeout the transaction. Resolution of this parameter is 33.3 ns. For simulation purposes it is recommended to set the value 48 [~1.6us] For synthesis purposes it is recommended to set the value 48 [~1.6us]
0x20200 VBP2APB_WRAP__CONTROLLER_VBP__CORE_ADDR_MAP_cfg_reg57 reset 0x2 — USB3.0 Configuration Register 57
  [1:0] LFPS_DEB_WIDTH rw — LFPS_DEB_WIDTH value This parameter defines the LFPS debouncer delay. Only two values are allowed: 0x1 or 0x2. For simulation purposes it is recommended to set the value 1. For synthesis purposes it is recommended to set the value 2.
0x20204 VBP2APB_WRAP__CONTROLLER_VBP__CORE_ADDR_MAP_cfg_reg58 reset 0x3D090 — USB3.0 Configuration Register 58
  [17:0] LFPS_GEN_U2EXIT rw — LFPS_GEN_U2EXIT value Resolution of this parameter is 8 ns. For simulation purposes it is recommended to set the value 62500 [~500us] For synthesis purposes it is recommended to set the value 250000 [~2ms]
0x20208 VBP2APB_WRAP__CONTROLLER_VBP__CORE_ADDR_MAP_cfg_reg59 reset 0x30D4 — USB3.0 Configuration Register 59
  [15:0] LFPS_MIN_GEN_U3EXIT rw — LFPS_MIN_GEN_U3EXIT value Resolution of this parameter is 8 ns. For simulation purposes it is recommended to set the value 12500 [~100us] For synthesis purposes it is recommended to set the value 12500 [~100us]
0x2020C VBP2APB_WRAP__CONTROLLER_VBP__CORE_ADDR_MAP_cfg_reg60 reset 0x15 — USB3.0 Configuration Register 60
  [6:0] PORT_CONFIG_TIMEOUT rw — PORT_CONFIG_TIMEOUT value Resolution of this parameter is 1 us. For simulation purposes it is recommended to set the value 21 [~20us] For synthesis purposes it is recommended to set the value 21 [~20us]
0x20210 VBP2APB_WRAP__CONTROLLER_VBP__CORE_ADDR_MAP_cfg_reg61 reset 0xFA — USB3.0 Configuration Register 61
  [10:0] LFPS_POL_LFPS_TO_RXEQ rw — LFPS_POL_LFPS_TO_RXEQ value Resolution of this parameter is 8 ns. For simulation purposes it is recommended to set the value 250 [~2us] For synthesis purposes it is recommended to set the value 250 [~2us]
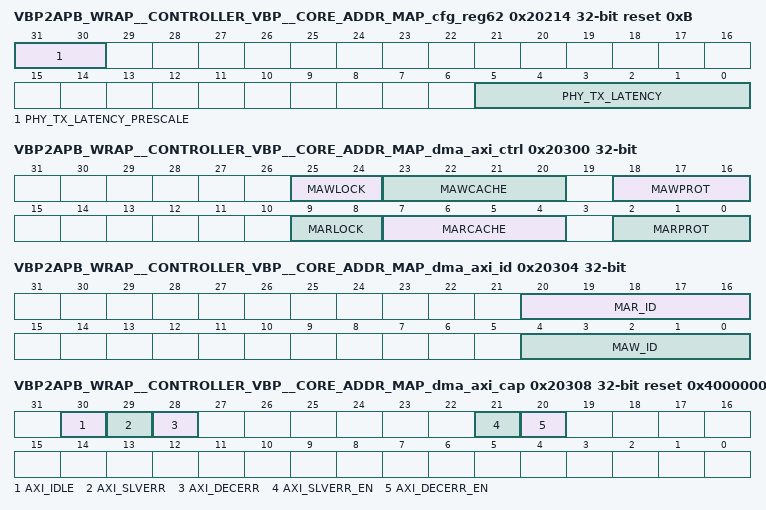
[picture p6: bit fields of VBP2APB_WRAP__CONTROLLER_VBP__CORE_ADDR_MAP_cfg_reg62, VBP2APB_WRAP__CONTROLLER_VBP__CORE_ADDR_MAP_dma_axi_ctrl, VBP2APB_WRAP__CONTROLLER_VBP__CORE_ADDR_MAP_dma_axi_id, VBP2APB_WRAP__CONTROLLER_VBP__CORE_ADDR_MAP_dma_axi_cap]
0x20214 VBP2APB_WRAP__CONTROLLER_VBP__CORE_ADDR_MAP_cfg_reg62 reset 0xB — USB3.0 Configuration Register 62
  [31:30] PHY_TX_LATENCY_PRESCALE rw — PRESCALER for PHY_TX_LATENCY value: - 0x0 : 8ns [PHY pclk clock] - 0x1 : 1us - 0x2 : 100us - 0x3 : no clock - allows disabling certain timeout
  [5:0] PHY_TX_LATENCY rw — PHY_TX_LATENCY value This parameter defines latency from when data appear on PIPE interface to channel + 3 time units [defined by PHY_TX_LATENCY_PRESCALE]. For simulation purposes it is recommended to set the value 11. For synthesis purposes it is recommended to set the value 11
0x20218 VBP2APB_WRAP__CONTROLLER_VBP__CORE_ADDR_MAP_cfg_reg63 reset 0x7CFF — USB3.0 Configuration Register 63
  [14:0] U2_INACTIVITY_TMOUT rw — U2_INACTIVITY_TMOUT value Resolution of this parameter is 8 ns. For simulation purposes it is recommended to set the value: - 31999*8ns =~256us [SystemC device ENV] - 249*8ns =~2us [VIP based ENV] For synthesis purposes it is recommended to set the value: - 31999*8ns =~256us
0x20220 VBP2APB_WRAP__CONTROLLER_VBP__CORE_ADDR_MAP_cfg_reg64 reset 0x4A — USB2.0 Configuration Register 64
  [6:0] TFILTSE0 rw — TFILTSE0: Reset Handshake Protocol: Time for which a suspended highspeed capable device must see a continuous SE0 before beginning the high-speed detection handshake. Resolution of this parameter is 33.3ns. For simulation purposes it is recommended to set the value: - 74*33.3ns =~2.46us [SystemC device ENV] - 57*33.3ns =~1.9us [VIP based ENV] For synthesis purposes it is recommended to set the value: - 74*33.3ns =~2.46us
0x20224 VBP2APB_WRAP__CONTROLLER_VBP__CORE_ADDR_MAP_cfg_reg65 reset 0x4B — USB2.0 Configuration Register 65
  [6:0] TFILT rw — TFILT: Time for which a Chirp J or Chirp K must be continuously detected [filtered] by hub or device during Reset handshake. Resolution of this parameter is 33.3 ns. For simulation purposes it is recommended to set the value: - 75*33.3ns =~2.5us [SystemC device ENV] - 57*33.3ns =~1.9us [VIP based ENV] For synthesis purposes it is recommended to set the value: - 75*33.3ns =~2.5us
0x20228 VBP2APB_WRAP__CONTROLLER_VBP__CORE_ADDR_MAP_cfg_reg66 reset 0x49 — USB2.0 Configuration Register 66
  [6:0] TWTRSTFS_SE0 rw — TWTRSTFS: Time a high-speed capable device operating in non-suspended fullspeed must wait after start of SE0 before beginning the high-speed detection handshake. Resolution of this parameter is 33.3 ns. For simulation purposes it is recommended to set the value: - 73*33.3ns =~2.43us [SystemC device ENV] - 57*33.3ns =~1.9us [VIP based ENV] For synthesis purposes it is recommended to set the value: - 73*33.3ns =~2.43us
0x20300 VBP2APB_WRAP__CONTROLLER_VBP__CORE_ADDR_MAP_dma_axi_ctrl — DMA AXI Master Control register. This register is optional, and implemented only when DMA has an AXI interface. This register configures the AXI master interface pins: marlock, marcache , marprot, mawlock, mawcache, mawprot are configurable by AXI Master Control register. The marcache and the mawcache width depends on the AXI release: AXI4/AXI3.
  [25:24] MAWLOCK rw — The mawlock pin configuration
  [23:20] MAWCACHE rw — The mawcache pin configuration
  [18:16] MAWPROT rw — The mawprot pin configuration
  [9:8] MARLOCK rw — The marlock pin configuration
  [7:4] MARCACHE rw — The marcache pin configuration
  [2:0] MARPROT rw — The marprot pin configuration
0x20304 VBP2APB_WRAP__CONTROLLER_VBP__CORE_ADDR_MAP_dma_axi_id — DMA AXI Master ID register. This register is optional, and implemented only when DMA has an AXI interface. Master ID width is configurable using CDNS_USBSSDEV_MAXI_ID_WIDTH define parameter (currently set to 4). Initially master will always output a value of zero regardless of the width. Value on the ID pins can be programmed using AXI Master ID register (DMA_AXI_ID) register.
  [20:16] MAR_ID rw — The marid pin configuration
  [4:0] MAW_ID rw — The mawid and mwid pin configuration
0x20308 VBP2APB_WRAP__CONTROLLER_VBP__CORE_ADDR_MAP_dma_axi_cap access not given reset 0x40000000 — DMA AXI Master Extended Capability register. This register is optional, and implemented only when DMA has an AXI interface. It contains status of this AXI interface operations.
  [30] AXI_IDLE ro — This bit provides information about the AXI Master state: '1': no pending action required by the AXI Master wrapper, '0': the AXI Master wrapper has outstanding transactions.
  [29] AXI_SLVERR — This bit provides an information about AXI SLAVE ERROR response on B or R channel. This flag is cleared by writing '1' to it. Once set it is held until cleared. (access R/W1TC)
  [28] AXI_DECERR — This bit provides an information about AXI DECODE ERROR response on B or R channel. This flag is cleared by writing '1' to it. Once set it is held until cleared. (access R/W1TC)
  [21] AXI_SLVERR_EN rw — This bit enables interrupt on AXI SLAVE ERROR detection. When 1 and AXI_SLVERR is 1 then AXI SLAVE ERROR interrupt is requested. When 0 - disabled interrupt from this source
  [20] AXI_DECERR_EN rw — This bit enables interrupt on AXI DECODE ERROR detection. When 1 and AXI_DECERR is 1 then AXI DECODE ERROR interrupt is requested. When 0 - disabled interrupt from this source
0x2030C VBP2APB_WRAP__CONTROLLER_VBP__CORE_ADDR_MAP_dma_axi_ctrl0 reset 0xF — DMA AXI Master Control0 register. This register is optional, and implemented only when DMA has an AXI interface with outstanding transactions support.
  [3:0] B_MAX rw — The register controls maximum burst length - it is used by the AXI Master wrapper to determine maximum value of AxLEN. It uses AXI AxLEN encoding. Default value is the maximum supported one and it is implementation specific. Width of this register is the same as AxLEN signals width. Note: This register should only be written to during the register initialisation process
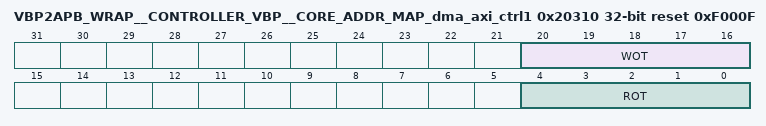
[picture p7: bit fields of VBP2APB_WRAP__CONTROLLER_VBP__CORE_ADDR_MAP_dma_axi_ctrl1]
0x20310 VBP2APB_WRAP__CONTROLLER_VBP__CORE_ADDR_MAP_dma_axi_ctrl1 reset 0xF000F — DMA AXI Master Control1 register. This register is optional, and implemented only when DMA has an AXI interface with outstanding transactions support.
  [20:16] WOT rw — Number of outstanding write transactions that can be initiated by the AXI Master wrapper. Default value of this field is CDNS_USBSSDEV_AXI_WCD-1 [define parameter]. The value written to this field should be the requested number of outstanding write transactions minus 1, thus the actual number of possible outstanding write transactions is one more than the programmed value. Note: This register should only be written to during the register initialization process
  [4:0] ROT rw — Number of outstanding read transactions that can be initiated by the AXI Master wrapper. Default value of this field is CDNS_USBSSDEV_AXI_WCD-1 [define parameter]. The value written to this field should be the requested number of outstanding read transactions minus 1, thus the actual number of possible outstanding read transactions is one more than the programmed value. Note: This register should only be written to during the register initialization process
0x20314 VBP2APB_WRAP__CONTROLLER_VBP__CORE_ADDR_MAP_dma_axi_ctrl2 reset 0x1 — AXI Master Wrapper Extended Capability Control Register 2. This register may be read from or written to at any time.
  [6:0] AXI_WTHRES rw — AXI Write Buffer Threshold, RW. When performing an AXI write burst this field specifies the minimum number of required AXI beats buffered prior to starting the burst on AXI W-Channel by asserting wvalid. This allows a user to balance the requirement for minimal latency with the requirement for low bus utilisation during bursts. Burst lengths smaller than or equal to this threshold will be buffered completely and then output on W-Channel. Burst lengths greater than this threshold will output the burst on the W-Channel such that the first AXI_WTHRES beats will be continuously with no drop of WVALID, beats thereafter may or may not be continuous depending on availability of data. Legal values are between 1 and 127. A value of 1 means that the burst is started on W-Channel as soon as any data is available without any additional delay. A value of 0 is reserved and should not be used as may lead to unpredictable behaviour. This register can be written only when the AXI Master wrapper is halted [AXI_HALT set to '1'] and idle [AXI_IDLE is '1']. Note: This register should only be written to during the register initialisation process.
